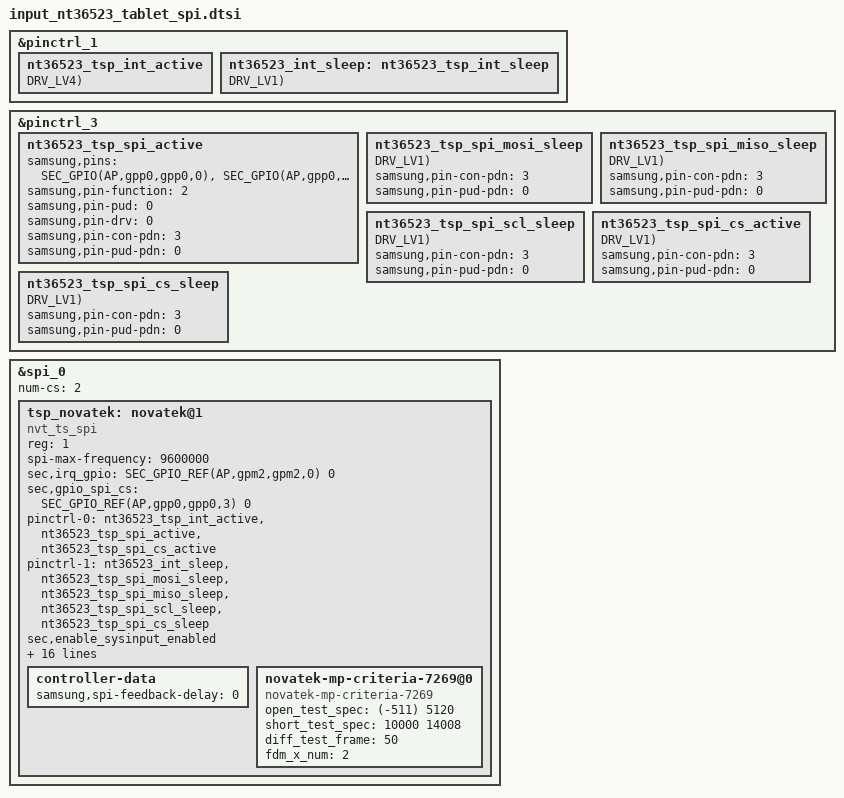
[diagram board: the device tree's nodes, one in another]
/*
 * SAMSUNG EXYNOS850 board common device tree source
 *
 * Copyright (c) 2019 Samsung Electronics Co., Ltd.
 *		http://www.samsung.com
 *
 * This program is free software; you can redistribute it and/or modify
 * it under the terms of the GNU General Public License version 2 as
 * published by the Free Software Foundation.
 */

&pinctrl_1 {
	nt36523_tsp_int_active: nt36523_tsp_int_active {
		GPIO_CONFIG_PUD_DRV(AP,gpm2,gpm2,0, FUNC_INPUT_WAKEUP, PULL_NONE, DRV_LV4);
	};

	nt36523_int_sleep: nt36523_tsp_int_sleep {
		GPIO_CONFIG_PUD_DRV(AP,gpm2,gpm2,0, FUNC_INPUT, PULL_DOWN, DRV_LV1);
	};
};

&pinctrl_3 {
	nt36523_tsp_spi_active: nt36523_tsp_spi_active {
		samsung,pins = SEC_GPIO(AP,gpp0,gpp0,0), SEC_GPIO(AP,gpp0,gpp0,1), SEC_GPIO(AP,gpp0,gpp0,2);
		samsung,pin-function = <2>;
		samsung,pin-pud = <0>;
		samsung,pin-drv = <0>;
		samsung,pin-con-pdn = <3>;
		samsung,pin-pud-pdn = <0>;
	};

	nt36523_tsp_spi_mosi_sleep: nt36523_tsp_spi_mosi_sleep {
		GPIO_CONFIG_PUD_DRV(AP,gpp0,gpp0,1, FUNC_INPUT, PULL_DOWN, DRV_LV1);
		samsung,pin-con-pdn = <3>;
		samsung,pin-pud-pdn = <0>;
	};

	nt36523_tsp_spi_miso_sleep: nt36523_tsp_spi_miso_sleep {
		GPIO_CONFIG_PUD_DRV(AP,gpp0,gpp0,2, FUNC_INPUT, PULL_DOWN, DRV_LV1);
		samsung,pin-con-pdn = <3>;
		samsung,pin-pud-pdn = <0>;
	};

	nt36523_tsp_spi_scl_sleep: nt36523_tsp_spi_scl_sleep {
		GPIO_CONFIG_PUD_DRV(AP,gpp0,gpp0,0, FUNC_INPUT, PULL_DOWN, DRV_LV1);
		samsung,pin-con-pdn = <3>;
		samsung,pin-pud-pdn = <0>;
	};

};

&pinctrl_3 {
	nt36523_tsp_spi_cs_active: nt36523_tsp_spi_cs_active {
		GPIO_CONFIG_PUD_DRV(AP,gpp0,gpp0,3, FUNC_OUTPUT_HIGH, PULL_NONE, DRV_LV1);
		samsung,pin-con-pdn = <3>;
		samsung,pin-pud-pdn = <0>;
	};

	nt36523_tsp_spi_cs_sleep: nt36523_tsp_spi_cs_sleep {
		GPIO_CONFIG_PUD_DRV(AP,gpp0,gpp0,3, FUNC_OUTPUT_LOW, PULL_NONE, DRV_LV1);
		samsung,pin-con-pdn = <3>;
		samsung,pin-pud-pdn = <0>;
	};
};

&spi_0 {
	#address-cells = <1>;
	#size-cells = <0>;
	status = "ok";
	pinctrl-names = "";
	num-cs = <1>;

	/* Novatek device tree node */
	tsp_novatek: novatek@1 {
		status = "okay";
		compatible = "nvt_ts_spi";
		reg = <1>; //Same as CS ID
		spi-max-frequency = <9600000>;

		sec,irq_gpio = <SEC_GPIO_REF(AP,gpm2,gpm2,0) 0>;
		sec,gpio_spi_cs = <SEC_GPIO_REF(AP,gpp0,gpp0,3) 0>;
		pinctrl-names = "on_state", "off_state";
		pinctrl-0 = <&nt36523_tsp_int_active &nt36523_tsp_spi_active &nt36523_tsp_spi_cs_active>;
		pinctrl-1 = <&nt36523_int_sleep &nt36523_tsp_spi_mosi_sleep &nt36523_tsp_spi_miso_sleep &nt36523_tsp_spi_scl_sleep &nt36523_tsp_spi_cs_sleep>;

		sec,enable_sysinput_enabled;
		support_vbus_notifier;

		controller-data {
			//cs-gpio = <SEC_GPIO_REF(AP,gpp0,gpp0,3) 0>;
			samsung,spi-feedback-delay = <0>;
		};
	};
};

/* /home/dpi/qb5_8814/workspace/P4_1716/kernel/kmodule/input/sec_input_2025/touchscreen/novatek/nt36523_tablet_spi/dts/input-lsi-tsp-nt36523-tablet_spi.gts10fe(wifi).dtsi */
&spi_0 {
	num-cs = <2>;
};

&tsp_novatek {
	sec,max_coords = <1440 2304>;
	support_dex_mode;
	enable_settings_aot;
	support_gesture_uevent;

	sec,bitmask_unload = <0x00FF00 0x00D200>; // unload if himax lcd
	sec,firmware_name = "nt36523_gts10fe_csot.bin";
	sec,firmware_name_mp = "nt36523_gts10fe_csot_mp.bin";

	not_support_vdd; // this is for sec_input.c
	novatek,name_lcd_rst = "lcd_rst";
	novatek,regulator_name = "lcd_vddi", "lcd_bl_en", "lcd_bl_en_2", "lcd_vsp", "lcd_vsn";

	/* 672A, 525B, 675, 526, 672C */
	novatek,swrst-n8-addr = <0x03F0FE>;
	novatek,spi-rd-fast-addr = <0x03F310>;

	/* MP */
	novatek,mp-support-dt;

	novatek-mp-criteria-7269@0 {
		#address-cells = <1>;
		#size-cells = <0>;
		compatible = "novatek-mp-criteria-7269";
		/* sec cmd test config */
		open_test_spec = <(-511) 5120>;
		short_test_spec = <10000 14008>;
		diff_test_frame = <50>;
		fdm_x_num = <2>;
	};
};

/* /home/dpi/qb5_8814/workspace/P4_1716/kernel/kmodule/input/sec_input_2025/touchscreen/novatek/nt36523_tablet_spi/dts/input-lsi-tsp-nt36523-tablet_spi.gts10fe(wifi).02.dtsi */
&tsp_novatek {
	novatek,regulator_name = "lcd_vddi", "lcd_bl_en", "lcd_vsp", "lcd_vsn";
};
